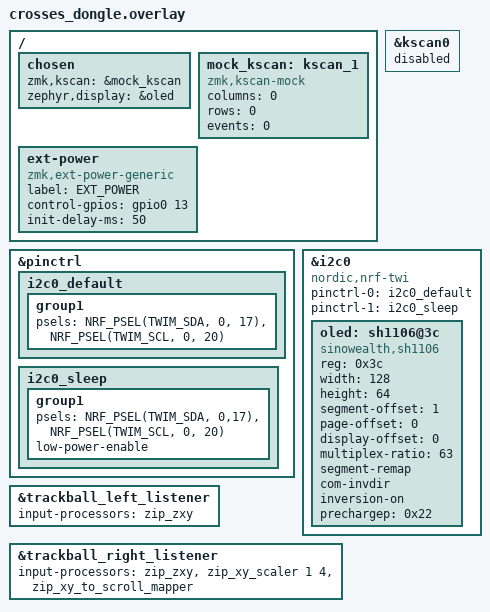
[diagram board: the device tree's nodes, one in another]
#include "crosses.dtsi"
#include "split_input.dtsi"
#include <input/processors.dtsi>
#include <input/processors/xyz.dtsi>
/ {
	chosen {
		zmk,kscan = &mock_kscan;
		zephyr,display = &oled;
	};

	mock_kscan: kscan_1 {
		compatible = "zmk,kscan-mock";
		columns = <0>;
		rows = <0>;
		events = <0>;
	};

    ext-power : ext-power {
        compatible = "zmk,ext-power-generic";
        label = "EXT_POWER";
        control-gpios = <&gpio0 13 GPIO_ACTIVE_HIGH>;
        init-delay-ms = <50>;
    };
};

&kscan0 {
	status = "disabled";
};



&pinctrl {
    i2c0_default: i2c0_default {
        group1 {
            psels = <NRF_PSEL(TWIM_SDA, 0, 17)>,
                <NRF_PSEL(TWIM_SCL, 0, 20)>;
        };
    };

    i2c0_sleep: i2c0_sleep {
        group1 {
            psels = <NRF_PSEL(TWIM_SDA, 0,17)>,
                <NRF_PSEL(TWIM_SCL, 0, 20)>;
            low-power-enable;
        };
    };	
}; 

&i2c0 {
	status = "okay";
	compatible = "nordic,nrf-twi";
    pinctrl-0 = <&i2c0_default>;
    pinctrl-1 = <&i2c0_sleep>;
	oled: sh1106@3c {
        compatible = "sinowealth,sh1106";
        reg = <0x3c>;
        width = <128>;
        height = <64>;
        segment-offset = <1>;
        page-offset = <0>;
        display-offset = <0>;
        multiplex-ratio = <63>;
        segment-remap;
        com-invdir;
        inversion-on;
        prechargep = <0x22>;
	};
};

&trackball_left_listener {
	status = "okay";
    input-processors =
        <&zip_zxy> // decompressor by badjeff. This needs to be at the head of the pipeline.
        ;
	
};

&trackball_right_listener {
	status = "okay";
    input-processors =
            <&zip_zxy>, // decompressor by badjeff
            <&zip_xy_scaler 1 4>,
            <&zip_xy_to_scroll_mapper>;        
};


